# PIC32MK0128MCA028 device description
Architecture: MIPS; Family: PIC32MK; Series: PIC32MK
Registers are 32-bit, read-write, no defined reset value unless marked. A register's access mark holds for its fields unless they carry their own. Offsets are from the block's base; [hi:lo] are bit positions; 'fields as' and 'values as' point back to an identical list.

## I2C
Instances: I2C 0x1f826000 in periph_pb2_std
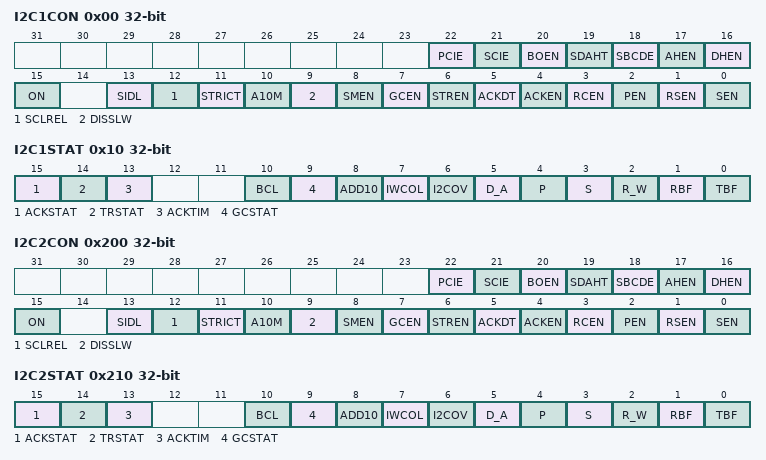
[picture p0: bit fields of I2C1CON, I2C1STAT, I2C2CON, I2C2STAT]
0x00 I2C1CON — I2C Control Register
  [22] PCIE — Stop Condition Interrupt Enable bit
    1=Enable interrupt on detection of Stop condition; 0=Stop detection interrupts are disabled
  [21] SCIE — Start Condition Interrupt Enable bit
    1=Enable interrupt on detection of Start or Restart conditions; 0=Start detection interrupts are disabled
  [20] BOEN — Buffer Overwrite Enable bit
    1=I2CxRCV is updated and an ACK is generated for a received address/data byte, ignoring the state of the I2COV bit (I2CxSTAT[6]) only if the RBF bit (I2CxSTAT[1]) = 0; 0=I2CxRCV is only updated when the I2COV bit (I2CxSTAT) is clear
  [19] SDAHT — SDA Hold Time Selection bit
    1=Minimum of 300 ns hold time on SDA after the falling edge of SCL; 0=Minimum of 100 ns hold time on SDA after the falling edge of SCL
  [18] SBCDE — Slave Mode Bus Collision Detect Enable bit
    1=Enable slave bus collision interrupts; 0=Slave bus collision interrupts are disabled
  [17] AHEN — Address Hold Enable bit
    1=Following the 8th falling edge of SCL for a matching received address byte; SCKREL bit will be cleared and the SCL will be held low; 0=Address holding is disabled
  [16] DHEN — Data Hold Enable bit
    1=Following the 8th falling edge of SCL for a received data byte; slave hardware clears the SCKREL bit and SCL is held low; 0=Data holding is disabled
  [15] ON — I2C Enable bit
    1=Enables the I2C module and configures the SDA and SCL pins as serial port pins; 0=Disables the I2C module; all I2C pins are controlled by PORT functions
  [13] SIDL — Stop in Idle Mode bit
    1=Discontinue module operation when device enters Idle mode; 0=Continue module operation in Idle mode
  [12] SCLREL — SCLx Release Control bit (when operating as I2C slave)
    1=Release SCLx clock; 0=Hold SCLx clock low (clock stretch)
  [11] STRICT — Strict I 2 C Reserved Address Rule Enable bit
    1=Strict reserved addressing is enforced. Device does not respond to reserved address space or generate addresses in reserved address space.; 0=Strict I2C Reserved Address Rule is not enabled
  [10] A10M — 10-bit Slave Address bit
  [9] DISSLW — Disable Slew Rate Control bit
    1=Slew rate control is disabled; 0=Slew rate control is enabled
  [8] SMEN — SMBus Input Levels bit
    1=Enable I/O pin thresholds compliant with SMBus specification; 0=Disable SMBus input thresholds
  [7] GCEN — General Call Enable bit
    1=Enable interrupt when a general call address is received in the I2CxRSR(module is enabled for reception); 0=General call address disabled
  [6] STREN — SCLx Clock Stretch Enable bit
    1=Enable software or receive clock stretching; 0=Disable software or receive clock stretching
  [5] ACKDT — Acknowledge Data bit
    1=Send NACK during Acknowledge; 0=Send ACK during Acknowledge
  [4] ACKEN — Acknowledge Sequence Enable bit
    1=Initiate Acknowledge sequence on SDAx and SCLx pins and transmit ACKDT data bit. Hardware clear at end of master Acknowledge sequence.; 0=Acknowledge sequence not in progress
  [3] RCEN — Receive Enable bit
    1=Enables Receive mode for I2C. Hardware clear at end of eighth bit of master receive data byte.; 0=Receive sequence not in progress
  [2] PEN — Stop Condition Enable bit
    1=Initiate Stop condition on SDAx and SCLx pins. Hardware clear at end of master Stop sequence.; 0=Stop condition not in progress
  [1] RSEN — Repeated Start Condition Enable bit
    1=Initiate Repeated Start condition on SDAx and SCLx pins. Hardware clear at end of master Repeated Start sequence.; 0=Repeated Start condition not in progress
  [0] SEN — Start Condition Enable bit
    1=Initiate Start condition on SDAx and SCLx pins. Hardware clear at end of master Start sequence.; 0=Start condition not in progress
0x10 I2C1STAT ro
  [15] ACKSTAT — Acknowledge Status bit
    1=Acknowledge was not received from slave; 0=Acknowledge was received from slave
  [14] TRSTAT — Transmit Status bit
    1=Master transmit is in progress (8 bits + ACK); 0=Master transmit is not in progress
  [13] ACKTIM — Acknowledge Time Status bit
    1=I2C bus is in an Acknowledge sequence; 0=Not an Acknowledge sequence
  [10] BCL — Master Bus Collision Detect bit
    1=A bus collision has been detected during a master operation; 0=No collision
  [9] GCSTAT — General Call Status bit
    1=General call address was received; 0=General call address was not received
  [8] ADD10 — 10-bit Address Status bit
    1=10-bit address was matched; 0=10-bit address was not matched
  [7] IWCOL — Write Collision Detect bit
    1=An attempt to write the I2CxTRN register failed because the I2C module is busy; 0=No collision
  [6] I2COV — Receive Overflow Flag bit
    1=A byte was received while the I2CxRCV register is still holding the previous byte; 0=No overflow
  [5] D_A — Data/Address bit (when operating as I2C slave)
    1=Indicates that the last byte received was data; 0=Indicates that the last byte received was device address
  [4] P — Stop bit
    1=Indicates that a Stop bit has been detected last; 0=Stop bit was not detected last
  [3] S — Start bit
    1=Indicates that a Start (or Repeated Start) bit has been detected last; 0=Start bit was not detected last
  [2] R_W — Read/Write Information bit (when operating as I2C slave)
    1=Read indicates data transfer is output from slave; 0=Write indicates data transfer is input to slave
  [1] RBF — Receive Buffer Full Status bit
    1=Receive complete I2CxRCV is full; 0=Receive not complete I2CxRCV is empty
  [0] TBF — Transmit Buffer Full Status bit
    1=Transmit in progress I2CxTRN is full; 0=Transmit complete I2CxTRN is empty
0x20 I2C1ADD
  [9:0] I2CADD
0x30 I2C1MSK
  [9:0] I2CMSK
0x40 I2C1BRG
  [15:0] I2CBRG
0x50 I2C1TRN wo
  [7:0] I2CTRN
0x60 I2C1RCV ro
  [7:0] I2CRCV
0x200 I2C2CON
  [22] PCIE — Stop Condition Interrupt Enable bit
    values as I2C1CON.PCIE
  [21] SCIE — Start Condition Interrupt Enable bit
    values as I2C1CON.SCIE
  [20] BOEN — Buffer Overwrite Enable bit
    values as I2C1CON.BOEN
  [19] SDAHT — SDA Hold Time Selection bit
    values as I2C1CON.SDAHT
  [18] SBCDE — Slave Mode Bus Collision Detect Enable bit
    values as I2C1CON.SBCDE
  [17] AHEN — Address Hold Enable bit
    values as I2C1CON.AHEN
  [16] DHEN — Data Hold Enable bit
    values as I2C1CON.DHEN
  [15] ON — I2C Enable bit
    values as I2C1CON.ON
  [13] SIDL — Stop in Idle Mode bit
    values as I2C1CON.SIDL
  [12] SCLREL — SCLx Release Control bit (when operating as I2C slave)
    1=Release SCLx clock; 0=Hold SCLx clock low (clock stretch)
  [11] STRICT — Strict I 2 C Reserved Address Rule Enable bit
    values as I2C1CON.STRICT
  [10] A10M — 10-bit Slave Address bit
  [9] DISSLW — Disable Slew Rate Control bit
    values as I2C1CON.DISSLW
  [8] SMEN — SMBus Input Levels bit
    values as I2C1CON.SMEN
  [7] GCEN — General Call Enable bit (when operating as I2C slave)
    values as I2C1CON.GCEN
  [6] STREN — SCLx Clock Stretch Enable bit (when operating as I2C slave)
    values as I2C1CON.STREN
  [5] ACKDT — Acknowledge Data bit (when operating as I2C master, applicable during master receive)
    values as I2C1CON.ACKDT
  [4] ACKEN — Acknowledge Sequence Enable bit
    values as I2C1CON.ACKEN
  [3] RCEN — Receive Enable bit (when operating as I2C master)
    values as I2C1CON.RCEN
  [2] PEN — Stop Condition Enable bit (when operating as I2C master)
    values as I2C1CON.PEN
  [1] RSEN — Repeated Start Condition Enable bit (when operating as I2C master)
    values as I2C1CON.RSEN
  [0] SEN — Start Condition Enable bit (when operating as I2C master)
    values as I2C1CON.SEN
0x210 I2C2STAT ro
  [15] ACKSTAT — Acknowledge Status bit (when operating as I2C master, applicable to master transmit operation)
    values as I2C1STAT.ACKSTAT
  [14] TRSTAT — Transmit Status bit (when operating as I2C master, applicable to master transmit operation)
    values as I2C1STAT.TRSTAT
  [13] ACKTIM — Acknowledge Time Status bit
    values as I2C1STAT.ACKTIM
  [10] BCL — Master Bus Collision Detect bit
    values as I2C1STAT.BCL
  [9] GCSTAT — General Call Status bit
    values as I2C1STAT.GCSTAT
  [8] ADD10 — 10-bit Address Status bit
    values as I2C1STAT.ADD10
  [7] IWCOL — Write Collision Detect bit
    values as I2C1STAT.IWCOL
  [6] I2COV — Receive Overflow Flag bit
    values as I2C1STAT.I2COV
  [5] D_A — Data/Address bit (when operating as I2C slave)
    values as I2C1STAT.D_A
  [4] P — Stop bit
    values as I2C1STAT.P
  [3] S — Start bit
    values as I2C1STAT.S
  [2] R_W — Read/Write Information bit (when operating as I2C slave)
    values as I2C1STAT.R_W
  [1] RBF — Receive Buffer Full Status bit
    values as I2C1STAT.RBF
  [0] TBF — Transmit Buffer Full Status bit
    values as I2C1STAT.TBF
0x220 I2C2ADD
  [9:0] I2CADD
0x230 I2C2MSK
  [9:0] I2CMSK
0x240 I2C2BRG
  [15:0] I2CBRG
0x250 I2C2TRN wo
  [7:0] I2CTRN
0x260 I2C2RCV ro
  [7:0] I2CRCV
